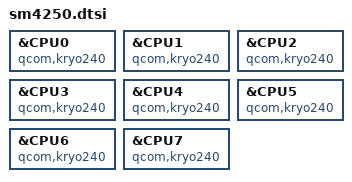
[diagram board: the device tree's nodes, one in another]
#include "sm6115.dtsi"
&CPU0 {
	compatible = "qcom,kryo240";
};
&CPU1 {
	compatible = "qcom,kryo240";
};
&CPU2 {
	compatible = "qcom,kryo240";
};
&CPU3 {
	compatible = "qcom,kryo240";
};
&CPU4 {
	compatible = "qcom,kryo240";
};
&CPU5 {
	compatible = "qcom,kryo240";
};
&CPU6 {
	compatible = "qcom,kryo240";
};
&CPU7 {
	compatible = "qcom,kryo240";
};
